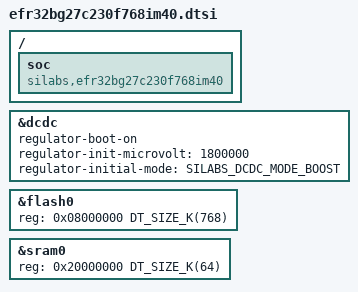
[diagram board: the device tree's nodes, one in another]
/*
 * Copyright (c) 2025 Silicon Laboratories Inc.
 *
 * SPDX-License-Identifier: Apache-2.0
 */

#include <mem.h>
#include <silabs/xg27/efr32bg27.dtsi>
#include <zephyr/dt-bindings/regulator/silabs_dcdc.h>

/ {
	soc {
		compatible = "silabs,efr32bg27c230f768im40", "silabs,efr32bg27", "silabs,xg27",
			     "silabs,efr32", "simple-bus";
	};
};

&dcdc {
	regulator-boot-on;
	regulator-init-microvolt = <1800000>;
	regulator-initial-mode = <SILABS_DCDC_MODE_BOOST>;
	status = "okay";
};

&flash0 {
	reg = <0x08000000 DT_SIZE_K(768)>;
};

&sram0 {
	reg = <0x20000000 DT_SIZE_K(64)>;
};
